# STM32F413 register map
File version: 1.9
CPU: CM4 r0p1, little endian, MPU, FPU, 4 interrupt priority bits
Registers are 32-bit, read-write, reset 0x0 unless marked. A register's access mark holds for its fields unless they carry their own. Offsets are from the block's base; [hi:lo] are bit positions; {n}, {i} and the like mark numbered series.

## GPIOF — General-purpose I/Os
Base 0x40021400
Same registers: GPIOC 0x40020800, GPIOD 0x40020C00, GPIOE 0x40021000, GPIOG 0x40021800, GPIOH 0x40021C00
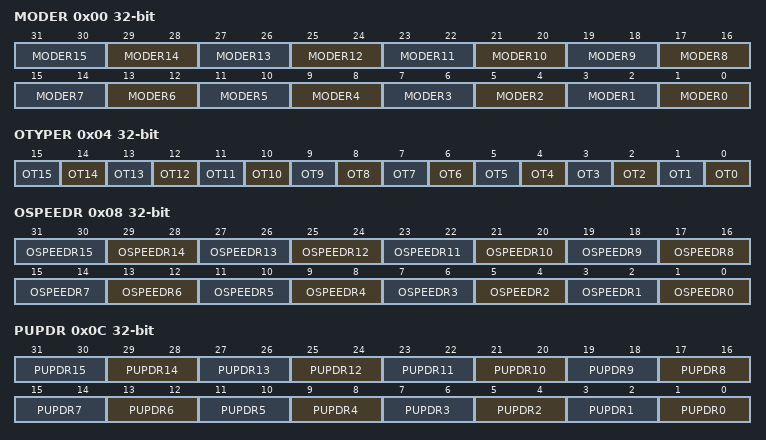
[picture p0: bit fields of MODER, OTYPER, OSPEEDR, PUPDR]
0x00 MODER — GPIO port mode register
  [2n+1:2n] MODER{n} (n=0..15) — Port x configuration bits (y = 0..15)
0x04 OTYPER — GPIO port output type register
  [n] OT{n} (n=0..15) — Port x configuration bits (y = 0..15)
0x08 OSPEEDR — GPIO port output speed register
  [2n+1:2n] OSPEEDR{n} (n=0..15) — Port x configuration bits (y = 0..15)
0x0C PUPDR — GPIO port pull-up/pull-down register
  [2n+1:2n] PUPDR{n} (n=0..15) — Port x configuration bits (y = 0..15)
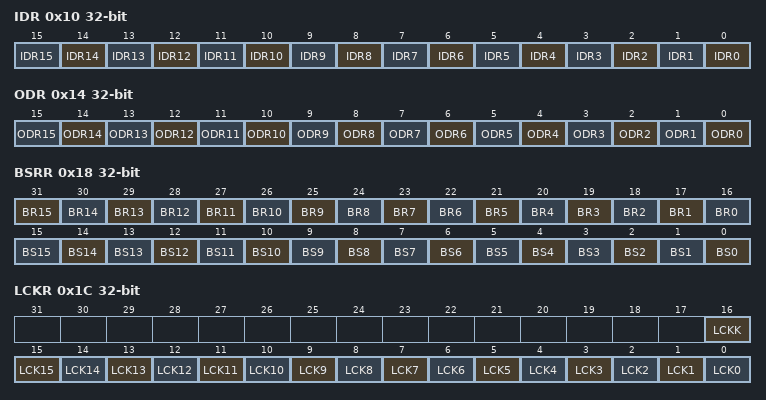
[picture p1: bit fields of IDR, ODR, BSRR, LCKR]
0x10 IDR ro — GPIO port input data register
  [n] IDR{n} (n=0..15) — Port input data (y = 0..15)
0x14 ODR — GPIO port output data register
  [n] ODR{n} (n=0..15) — Port output data (y = 0..15)
0x18 BSRR wo — GPIO port bit set/reset register
  [n+16] BR{n} (n=1..15) — Port x reset bit y (y = 0..15)
  [16] BR0 — Port x set bit y (y= 0..15)
  [n] BS{n} (n=0..15) — Port x set bit y (y= 0..15)
0x1C LCKR — GPIO port configuration lock register
  [16] LCKK — Port x lock bit y (y= 0..15)
  [n] LCK{n} (n=0..15) — Port x lock bit y (y= 0..15)
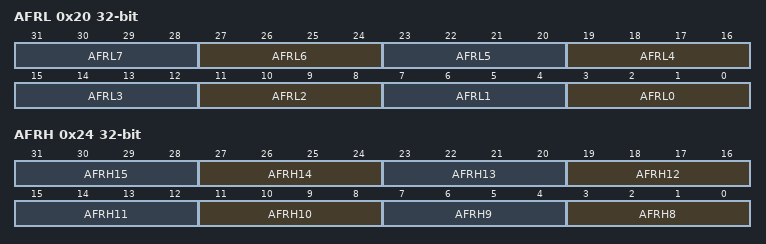
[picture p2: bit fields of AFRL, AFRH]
0x20 AFRL — GPIO alternate function low register
  [4n+3:4n] AFRL{n} (n=0..7) — Alternate function selection for port x bit y (y = 0..7)
0x24 AFRH — GPIO alternate function high register
  [4n-29:4n-32] AFRH{n} (n=8..15) — Alternate function selection for port x bit y (y = 8..15)

## GPIOB — General-purpose I/Os
Base 0x40020400
Registers as GPIOF; these are added or differ:
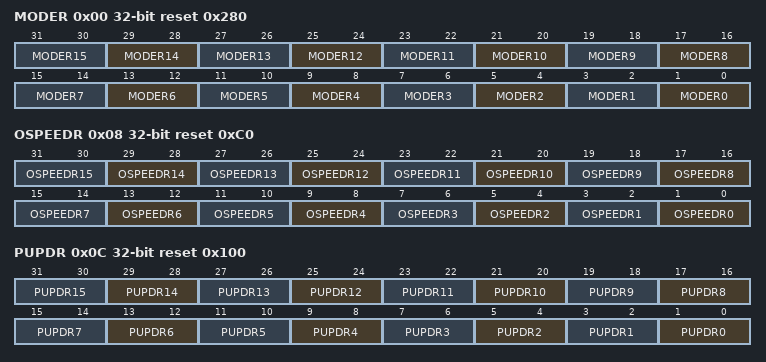
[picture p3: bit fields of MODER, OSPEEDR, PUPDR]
0x00 MODER reset 0x280 — GPIO port mode register
  [2n+1:2n] MODER{n} (n=0..15) — Port x configuration bits (y = 0..15)
0x08 OSPEEDR reset 0xC0 — GPIO port output speed register
  [2n+1:2n] OSPEEDR{n} (n=0..15) — Port x configuration bits (y = 0..15)
0x0C PUPDR reset 0x100 — GPIO port pull-up/pull-down register
  [2n+1:2n] PUPDR{n} (n=0..15) — Port x configuration bits (y = 0..15)

## GPIOA — General-purpose I/Os
Base 0x40020000
Registers as GPIOF; these are added or differ:
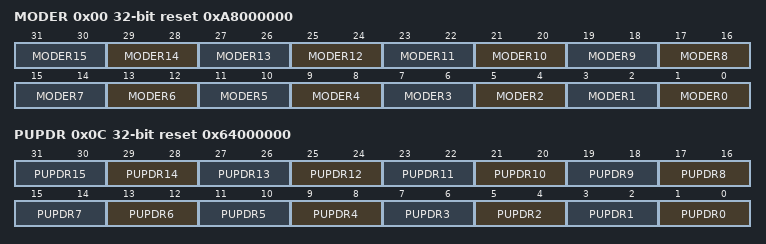
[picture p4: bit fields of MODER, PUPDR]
0x00 MODER reset 0xA8000000 — GPIO port mode register
  [2n+1:2n] MODER{n} (n=0..15) — Port x configuration bits (y = 0..15)
0x0C PUPDR reset 0x64000000 — GPIO port pull-up/pull-down register
  [2n+1:2n] PUPDR{n} (n=0..15) — Port x configuration bits (y = 0..15)

## IWDG — Independent watchdog
Base 0x40003000
0x00 KR wo — Key register
  [15:0] KEY — Key value
0x04 PR — Prescaler register
  [2:0] PR — Prescaler divider
0x08 RLR reset 0xFFF — Reload register
  [11:0] RL — Watchdog counter reload value
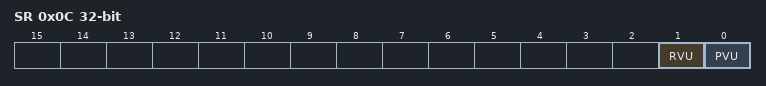
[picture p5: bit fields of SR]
0x0C SR ro — Status register
  [1] RVU — Watchdog counter reload value update
  [0] PVU — Watchdog prescaler value update

## I2C2 — Inter-integrated circuit
Base 0x40005800
Same registers: I2C1 0x40005400, I2C3 0x40005C00
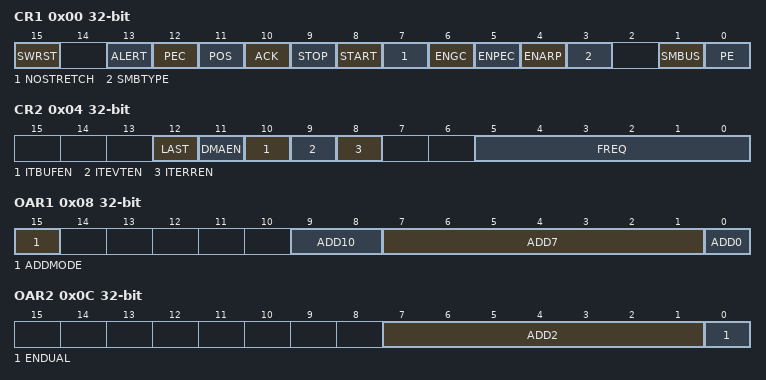
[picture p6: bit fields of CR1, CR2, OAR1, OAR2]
0x00 CR1 — Control register 1
  [15] SWRST — Software reset
  [13] ALERT — SMBus alert
  [12] PEC — Packet error checking
  [11] POS — Acknowledge/PEC Position (for data reception)
  [10] ACK — Acknowledge enable
  [9] STOP — Stop generation
  [8] START — Start generation
  [7] NOSTRETCH — Clock stretching disable (Slave mode)
  [6] ENGC — General call enable
  [5] ENPEC — PEC enable
  [4] ENARP — ARP enable
  [3] SMBTYPE — SMBus type
  [1] SMBUS — SMBus mode
  [0] PE — Peripheral enable
0x04 CR2 — Control register 2
  [12] LAST — DMA last transfer
  [11] DMAEN — DMA requests enable
  [10] ITBUFEN — Buffer interrupt enable
  [9] ITEVTEN — Event interrupt enable
  [8] ITERREN — Error interrupt enable
  [5:0] FREQ — Peripheral clock frequency
0x08 OAR1 — Own address register 1
  [15] ADDMODE — Addressing mode (slave mode)
  [9:8] ADD10 — Interface address
  [7:1] ADD7 — Interface address
  [0] ADD0 — Interface address
0x0C OAR2 — Own address register 2
  [7:1] ADD2 — Interface address
  [0] ENDUAL — Dual addressing mode enable
0x10 DR — Data register
  [7:0] DR — 8-bit data register
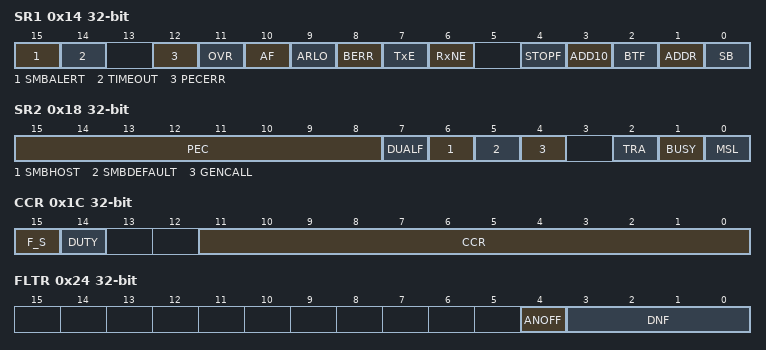
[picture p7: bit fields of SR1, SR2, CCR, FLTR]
0x14 SR1 access per field — Status register 1
  [15] SMBALERT rw write-0-clears — SMBus alert
  [14] TIMEOUT rw write-0-clears — Timeout or Tlow error
  [12] PECERR rw write-0-clears — PEC Error in reception
  [11] OVR rw write-0-clears — Overrun/Underrun
  [10] AF rw write-0-clears — Acknowledge failure
  [9] ARLO rw write-0-clears — Arbitration lost (master mode)
  [8] BERR rw write-0-clears — Bus error
  [7] TxE ro — Data register empty (transmitters)
  [6] RxNE ro — Data register not empty (receivers)
  [4] STOPF ro — Stop detection (slave mode)
  [3] ADD10 ro — 10-bit header sent (Master mode)
  [2] BTF ro — Byte transfer finished
  [1] ADDR ro — Address sent (master mode)/matched (slave mode)
  [0] SB ro — Start bit (Master mode)
0x18 SR2 ro — Status register 2
  [15:8] PEC — acket error checking register
  [7] DUALF — Dual flag (Slave mode)
  [6] SMBHOST — SMBus host header (Slave mode)
  [5] SMBDEFAULT — SMBus device default address (Slave mode)
  [4] GENCALL — General call address (Slave mode)
  [2] TRA — Transmitter/receiver
  [1] BUSY — Bus busy
  [0] MSL — Master/slave
0x1C CCR — Clock control register
  [15] F_S — I2C master mode selection
  [14] DUTY — Fast mode duty cycle
  [11:0] CCR — Clock control register in Fast/Standard mode (Master mode)
0x20 TRISE reset 0x2
  [5:0] TRISE — Maximum rise time in Fast/Standard mode (Master mode)
0x24 FLTR
  [4] ANOFF — Analog noise filter OFF
  [3:0] DNF — Digital noise filter
